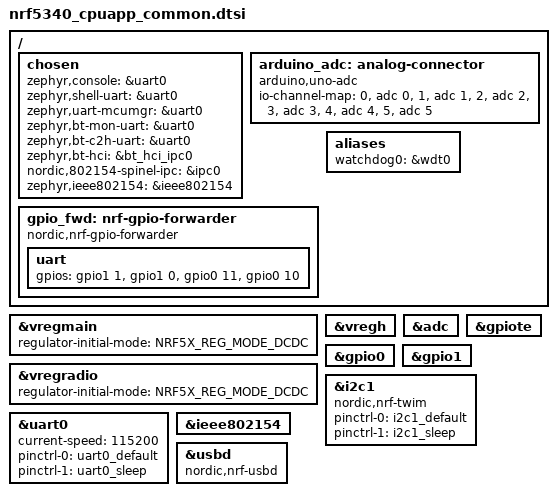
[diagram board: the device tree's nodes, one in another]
/*
 * Copyright (c) 2019-2020 Nordic Semiconductor ASA
 *
 * SPDX-License-Identifier: Apache-2.0
 */
#include "nrf5340dk_common.dtsi"
#include "nrf5340_cpuapp_common-pinctrl.dtsi"
#include <zephyr/dt-bindings/input/input-event-codes.h>

/ {

	chosen {
		zephyr,console = &uart0;
		zephyr,shell-uart = &uart0;
		zephyr,uart-mcumgr = &uart0;
		zephyr,bt-mon-uart = &uart0;
		zephyr,bt-c2h-uart = &uart0;
		zephyr,bt-hci = &bt_hci_ipc0;
		nordic,802154-spinel-ipc = &ipc0;
		zephyr,ieee802154 = &ieee802154;
	};


	arduino_adc: analog-connector {
		compatible = "arduino,uno-adc";
		#io-channel-cells = <1>;
		io-channel-map = <0 &adc 0>,	/* A0 = P0.4 = AIN0 */
				 <1 &adc 1>,	/* A1 = P0.5 = AIN1 */
				 <2 &adc 2>,	/* A2 = P0.6 = AIN2 */
				 <3 &adc 3>,	/* A3 = P0.7 = AIN3 */
				 <4 &adc 4>,	/* A4 = P0.25 = AIN4 */
				 <5 &adc 5>;	/* A5 = P0.26 = AIN5 */
	};

	gpio_fwd: nrf-gpio-forwarder {
		compatible = "nordic,nrf-gpio-forwarder";
		status = "okay";
		uart {
			gpios = <&gpio1 1 0>, <&gpio1 0 0>, <&gpio0 11 0>, <&gpio0 10 0>;
		};
	};

	/* These aliases are provided for compatibility with samples */
	aliases {
		watchdog0 = &wdt0;
	};
};

&vregmain {
	regulator-initial-mode = <NRF5X_REG_MODE_DCDC>;
};

&vregradio {
	regulator-initial-mode = <NRF5X_REG_MODE_DCDC>;
};

&vregh {
	status = "okay";
};

&adc {
	status = "okay";
};

&gpiote {
	status = "okay";
};

&gpio0 {
	status = "okay";
};

&gpio1 {
	status = "okay";
};

&i2c1 {
	compatible = "nordic,nrf-twim";
	status = "okay";
	pinctrl-0 = <&i2c1_default>;
	pinctrl-1 = <&i2c1_sleep>;
	pinctrl-names = "default", "sleep";
};

&uart0 {
	status = "okay";
	current-speed = <115200>;
	pinctrl-0 = <&uart0_default>;
	pinctrl-1 = <&uart0_sleep>;
	pinctrl-names = "default", "sleep";
};

&ieee802154 {
	status = "okay";
};

zephyr_udc0: &usbd {
	compatible = "nordic,nrf-usbd";
	status = "okay";
};

/* Include default memory partition configuration file */
#include <common/nordic/nrf5340_cpuapp_partition.dtsi>
